# ATSAMA5D24 device description
Architecture: CORTEX-A5; Family: SAMA5D2; Series: SAMA5D2
Registers are 32-bit, read-write, no defined reset value unless marked. A register's access mark holds for its fields unless they carry their own. Offsets are from the block's base; [hi:lo] are bit positions; {n}, {i} and the like mark numbered series; 'fields as' and 'values as' point back to an identical list; <NAME> marks a mode.

## PIO — Parallel Input/Output Controller
Instances: PIOA 0xFC038000, PIOB 0xFC038040, PIOC 0xFC038080, PIOD 0xFC0380C0
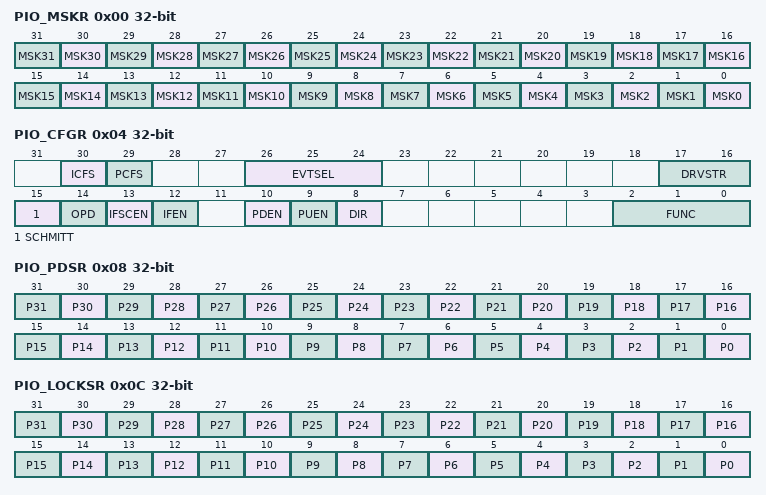
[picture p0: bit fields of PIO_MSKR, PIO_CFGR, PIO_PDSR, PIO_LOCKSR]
0x00 PIO_MSKR — PIO Mask Register
  [all] fields
    0=DISABLED (Writing the PIO_CFGRx, PIO_ODSRx or PIO_IOFRx does not affect the corresponding I/O line configuration.); 1=ENABLED (Writing the PIO_CFGRx, PIO_ODSRx or PIO_IOFRx updates the corresponding I/O line configuration.)
  [n] MSK{n} (n=0..31) — PIO Line {n} Mask
0x04 PIO_CFGR — PIO Configuration Register
  [30] ICFS — Interrupt Configuration Freeze Status (read-only)
    0=NOT_FROZEN (The fields are not frozen and can be written for this I/O line.); 1=FROZEN (The fields are frozen and cannot be written for this I/O line. Only a hardware reset can release these fields.)
  [29] PCFS — Physical Configuration Freeze Status (read-only)
    values as ICFS
  [26:24] EVTSEL — Event Selection
    0=FALLING (Event detection on input falling edge); 1=RISING (Event detection on input rising edge); 2=BOTH (Event detection on input both edge); 3=LOW (Event detection on low level input); 4=HIGH (Event detection on high level input)
  [17:16] DRVSTR — Drive Strength
    1=LO (Low drive); 2=ME (Medium drive); 3=HI (High drive)
  [15] SCHMITT — Schmitt Trigger
    0=ENABLED (Schmitt trigger is enabled for the selected I/O lines.); 1=DISABLED (Schmitt trigger is disabled for the selected I/O lines.)
  [14] OPD — Open-Drain
    0=DISABLED (The open-drain is disabled for the selected I/O lines. I/O lines are driven at high- and low-level.); 1=ENABLED (The open-drain is enabled for the selected I/O lines. I/O lines are driven at low-level only.)
  [13] IFSCEN — Input Filter Slow Clock Enable
    0=DISABLED (The glitch filter is able to filter glitches with a duration < tmck/2 for the selected I/O lines.); 1=ENABLED (The debouncing filter is able to filter pulses with a duration < tdiv_slck/2 for the selected I/O lines.)
  [12] IFEN — Input Filter Enable
    0=DISABLED (The input filter is disabled for the selected I/O lines.); 1=ENABLED (The input filter is enabled for the selected I/O lines.)
  [10] PDEN — Pull-Down Enable
    0=DISABLED (Pull-Down is disabled for the selected I/O lines.); 1=ENABLED (Pull-Down is enabled for the selected I/O lines only if PUEN is 0(1).)
  [9] PUEN — Pull-Up Enable
    0=DISABLED (Pull-Up is disabled for the selected I/O lines.); 1=ENABLED (Pull-Up is enabled for the selected I/O lines.)
  [8] DIR — Direction
    0=INPUT (The selected I/O lines are pure inputs.); 1=OUTPUT (The selected I/O lines are enabled in output.)
  [2:0] FUNC — I/O Line Function
    0=GPIO (Select the PIO mode for the selected I/O lines.); 1=PERIPH_A (Select the peripheral A for the selected I/O lines.); 2=PERIPH_B (Select the peripheral B for the selected I/O lines.); 3=PERIPH_C (Select the peripheral C for the selected I/O lines.); 4=PERIPH_D (Select the peripheral D for the selected I/O lines.); 5=PERIPH_E (Select the peripheral E for the selected I/O lines.); 6=PERIPH_F (Select the peripheral F for the selected I/O lines.); 7=PERIPH_G (Select the peripheral G for the selected I/O lines.)
0x08 PIO_PDSR ro — PIO Pin Data Status Register
  [n] P{n} (n=0..31) — Input Data Status
0x0C PIO_LOCKSR ro — PIO Lock Status Register
  [n] P{n} (n=0..31) — Lock Status
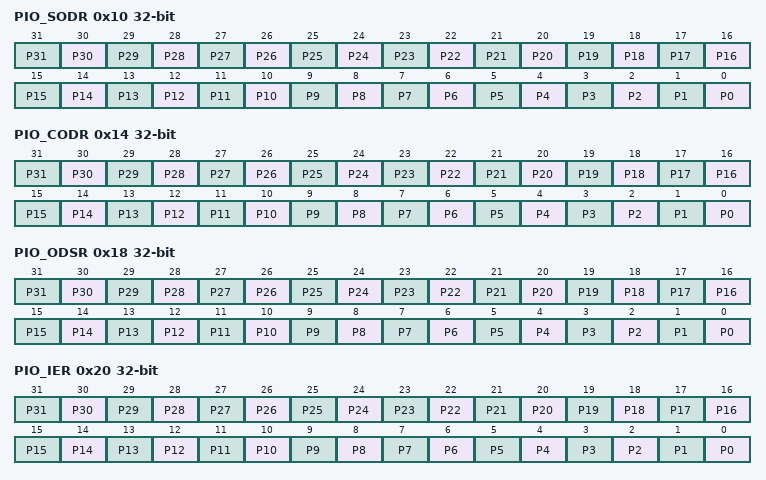
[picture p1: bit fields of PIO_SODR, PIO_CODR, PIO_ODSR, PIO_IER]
0x10 PIO_SODR wo — PIO Set Output Data Register
  [n] P{n} (n=0..31) — Set Output Data
0x14 PIO_CODR wo — PIO Clear Output Data Register
  [n] P{n} (n=0..31) — Clear Output Data
0x18 PIO_ODSR — PIO Output Data Status Register
  [n] P{n} (n=0..31) — Output Data Status
0x20 PIO_IER wo (atomic set of PIO_IMR) — PIO Interrupt Enable Register
  [n] P{n} (n=0..31) — Input Change Interrupt Enable
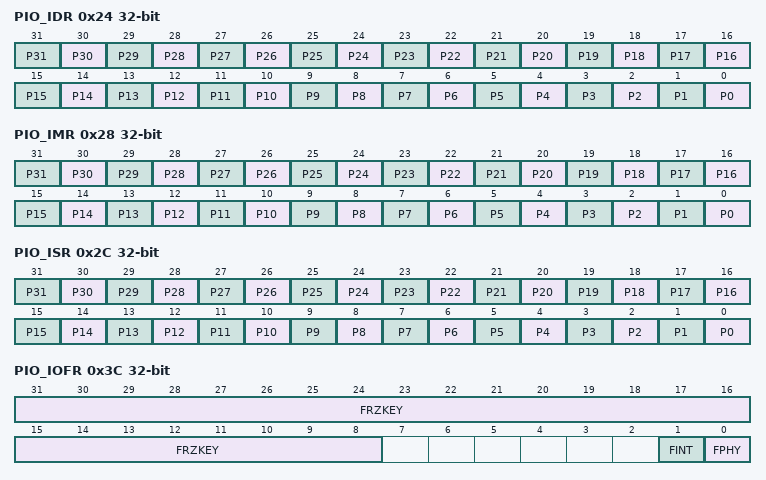
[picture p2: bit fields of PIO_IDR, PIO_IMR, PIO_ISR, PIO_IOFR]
0x24 PIO_IDR wo (atomic clear of PIO_IMR) — PIO Interrupt Disable Register
  [n] P{n} (n=0..31) — Input Change Interrupt Disable
0x28 PIO_IMR ro (atomic read) — PIO Interrupt Mask Register
  [n] P{n} (n=0..31) — Input Change Interrupt Mask
0x2C PIO_ISR ro (atomic clear) — PIO Interrupt Status Register
  [n] P{n} (n=0..31) — Input Change Interrupt Status
0x3C PIO_IOFR wo — PIO I/O Freeze Configuration Register
  [31:8] FRZKEY — Freeze Key
    0x494F46=PASSWD (Writing any other value in this field aborts the write operation of the WPEN bit.)
  [1] FINT — Freeze Interrupt Configuration
  [0] FPHY — Freeze Physical Configuration

## Notices in the file
Copyright (c) 2017 Microchip Technology Inc.
SPDX-License-Identifier: Apache-2.0
Licensed under the Apache License, Version 2.0 (the "License");
you may not use this file except in compliance with the License.
You may obtain a copy of the License at
http://www.apache.org/licenses/LICENSE-2.0
Unless required by applicable law or agreed to in writing, software
distributed under the License is distributed on an "AS IS" BASIS,
WITHOUT WARRANTIES OR CONDITIONS OF ANY KIND, either express or implied.
See the License for the specific language governing permissions and
limitations under the License.
